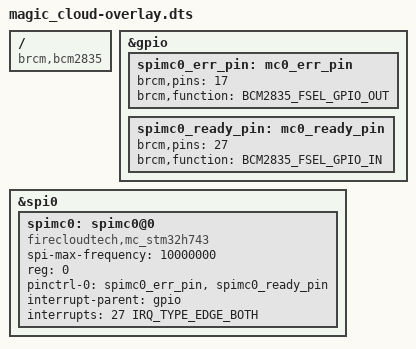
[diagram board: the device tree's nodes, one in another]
/dts-v1/;
/plugin/;

#include <dt-bindings/gpio/gpio.h>
#include <dt-bindings/interrupt-controller/irq.h>
#include <dt-bindings/pinctrl/bcm2835.h>

/ {
    compatible = "brcm,bcm2835";

	fragment@0 {
		target = <&spi0>;
		__dormant__ {
			status = "okay";
		};
	};

	fragment@1 {
		target = <&gpio>;
		__overlay__ {
			spimc0_err_pin: mc0_err_pin {
				brcm,pins = <17>;
				brcm,function = <BCM2835_FSEL_GPIO_OUT>;
			};
			spimc0_ready_pin: mc0_ready_pin {
				brcm,pins = <27>;
				brcm,function = <BCM2835_FSEL_GPIO_IN>;
			};
		};
	};

    spimc_frag: fragment@2 {
		target = <&spi0>;
		__overlay__ {
			status = "okay";
			#address-cells = <1>;
			#size-cells = <0>;

			spimc0: spimc0@0 {
				compatible = "firecloudtech,mc_stm32h743";
                spi-max-frequency = <10000000>;
				reg = <0>;
				//spi-cpol;
				//spi-cpha;
				pinctrl-names = "spimc_err_pin", "spimc_ready_pin";
				pinctrl-0 = <&spimc0_err_pin>, <&spimc0_ready_pin>;
				interrupt-parent = <&gpio>;
				interrupts = <27 IRQ_TYPE_EDGE_BOTH>;
				//dmas = <&dma 6>, <&dma 7>;
				//dma-names = "tx", "rx";
			};
		};
	};
};
